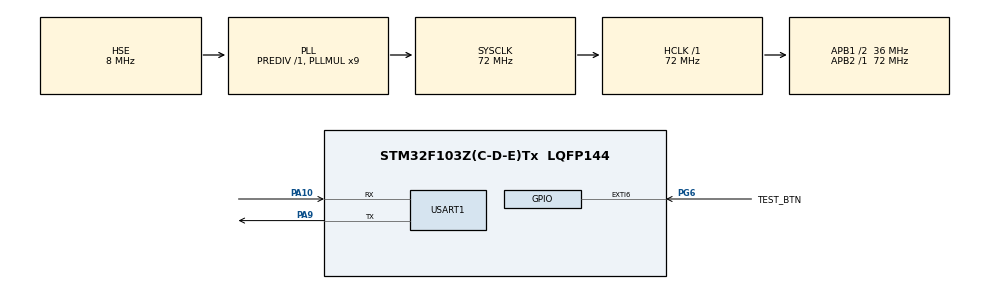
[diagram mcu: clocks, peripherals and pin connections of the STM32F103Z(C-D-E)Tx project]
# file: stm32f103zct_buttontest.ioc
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Mcu.Family=STM32F1
RCC.PLLSourceVirtual=RCC_PLLSOURCE_HSE
PC15-OSC32_OUT.Mode=LSE-External-Oscillator
PG6.Signal=GPXTI6
PA10.Mode=Asynchronous
PG6.GPIO_Label=TEST_BTN
RCC.APB1CLKDivider=RCC_HCLK_DIV2
PC14-OSC32_IN.Signal=RCC_OSC32_IN
RCC.SYSCLKSource=RCC_SYSCLKSOURCE_PLLCLK
ProjectManager.StackSize=0x400
PA13.Signal=SYS_JTMS-SWDIO
PA9.Mode=Asynchronous
ProjectManager.TargetToolchain=STM32CubeIDE
RCC.HCLKFreq_Value=72000000
RCC.APB2TimFreq_Value=72000000
PA9.Signal=USART1_TX
OSC_IN.Signal=RCC_OSC_IN
RCC.USBFreq_Value=72000000
OSC_OUT.Mode=HSE-External-Oscillator
PC15-OSC32_OUT.Signal=RCC_OSC32_OUT
OSC_OUT.Signal=RCC_OSC_OUT
RCC.AHBFreq_Value=72000000
board=custom
RCC.PLLMUL=RCC_PLL_MUL9
RCC.APB2Freq_Value=72000000
PG6.GPIO_PuPd=GPIO_PULLUP
PC14-OSC32_IN.Mode=LSE-External-Oscillator
PA14.Mode=Serial_Wire
PG6.GPIO_ModeDefaultEXTI=GPIO_MODE_IT_RISING_FALLING
PA13.Mode=Serial_Wire
Mcu.Name=STM32F103Z(C-D-E)Tx
RCC.SYSCLKFreq_VALUE=72000000
Mcu.Package=LQFP144
OSC_IN.Mode=HSE-External-Oscillator
USART1.VirtualMode=VM_ASYNC
NVIC.EXTI9_5_IRQn=true\:0\:0\:false\:false\:true\:true\:true
PA10.Signal=USART1_RX
PA14.Signal=SYS_JTCK-SWCLK
ProjectManager.HeapSize=0x200
NVIC.PriorityGroup=NVIC_PRIORITYGROUP_4
RCC.APB1TimFreq_Value=72000000
RCC.APB1Freq_Value=36000000

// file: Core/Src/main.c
/* USER CODE BEGIN Header */
/**
  ******************************************************************************
  * @file           : main.c
  * @brief          : Main program body
  ******************************************************************************
  * @attention
  *
  * <h2><center>&copy; Copyright (c) 2021 STMicroelectronics.
  * All rights reserved.</center></h2>
  *
  * This software component is licensed by ST under BSD 3-Clause license,
  * the "License"; You may not use this file except in compliance with the
  * License. You may obtain a copy of the License at:
  *                        opensource.org/licenses/BSD-3-Clause
  *
  ******************************************************************************
  */
/* USER CODE END Header */
#include "main.h"

/* USER CODE BEGIN Includes */
#include "Application.h"
/* USER CODE END Includes */

UART_HandleTypeDef huart1;

void SystemClock_Config(void);
static void MX_GPIO_Init(void);
static void MX_USART1_UART_Init(void);

int main(void)
{

    /* MCU Configuration--------------------------------------------------------*/

    /* Reset of all peripherals, Initializes the Flash interface and the Systick. */
    HAL_Init();

    /* Configure the system clock */
    SystemClock_Config();

    /* Initialize all configured peripherals */
    MX_GPIO_Init();
    MX_USART1_UART_Init();
    /* USER CODE BEGIN 2 */
    Application.init();
    /* USER CODE END 2 */

    /* Infinite loop */
    while (1) {
        Application.loop();
    }
}

void SystemClock_Config(void)
{
    RCC_OscInitTypeDef RCC_OscInitStruct = { 0 };
    RCC_ClkInitTypeDef RCC_ClkInitStruct = { 0 };

    /** Initializes the RCC Oscillators according to the specified parameters
  * in the RCC_OscInitTypeDef structure.
  */
    RCC_OscInitStruct.OscillatorType = RCC_OSCILLATORTYPE_HSE;
    RCC_OscInitStruct.HSEState = RCC_HSE_ON;
    RCC_OscInitStruct.HSEPredivValue = RCC_HSE_PREDIV_DIV1;
    RCC_OscInitStruct.HSIState = RCC_HSI_ON;
    RCC_OscInitStruct.PLL.PLLState = RCC_PLL_ON;
    RCC_OscInitStruct.PLL.PLLSource = RCC_PLLSOURCE_HSE;
    RCC_OscInitStruct.PLL.PLLMUL = RCC_PLL_MUL9;
    if (HAL_RCC_OscConfig(&RCC_OscInitStruct) != HAL_OK) {
        Error_Handler();
    }
    /** Initializes the CPU, AHB and APB buses clocks
  */
    RCC_ClkInitStruct.ClockType = RCC_CLOCKTYPE_HCLK | RCC_CLOCKTYPE_SYSCLK
        | RCC_CLOCKTYPE_PCLK1 | RCC_CLOCKTYPE_PCLK2;
    RCC_ClkInitStruct.SYSCLKSource = RCC_SYSCLKSOURCE_PLLCLK;
    RCC_ClkInitStruct.AHBCLKDivider = RCC_SYSCLK_DIV1;
    RCC_ClkInitStruct.APB1CLKDivider = RCC_HCLK_DIV2;
    RCC_ClkInitStruct.APB2CLKDivider = RCC_HCLK_DIV1;

    if (HAL_RCC_ClockConfig(&RCC_ClkInitStruct, FLASH_LATENCY_2) != HAL_OK) {
        Error_Handler();
    }
}

static void MX_USART1_UART_Init(void)
{

    huart1.Instance = USART1;
    huart1.Init.BaudRate = 115200;
    huart1.Init.WordLength = UART_WORDLENGTH_8B;
    huart1.Init.StopBits = UART_STOPBITS_1;
    huart1.Init.Parity = UART_PARITY_NONE;
    huart1.Init.Mode = UART_MODE_TX_RX;
    huart1.Init.HwFlowCtl = UART_HWCONTROL_NONE;
    huart1.Init.OverSampling = UART_OVERSAMPLING_16;
    if (HAL_UART_Init(&huart1) != HAL_OK) {
        Error_Handler();
    }
}

static void MX_GPIO_Init(void)
{
    GPIO_InitTypeDef GPIO_InitStruct = { 0 };

    /* GPIO Ports Clock Enable */
    __HAL_RCC_GPIOC_CLK_ENABLE();
    __HAL_RCC_GPIOG_CLK_ENABLE();
    __HAL_RCC_GPIOA_CLK_ENABLE();

    /*Configure GPIO pin : TEST_BTN_Pin */
    GPIO_InitStruct.Pin = TEST_BTN_Pin;
    GPIO_InitStruct.Mode = GPIO_MODE_IT_RISING_FALLING;
    GPIO_InitStruct.Pull = GPIO_PULLUP;
    HAL_GPIO_Init(TEST_BTN_GPIO_Port, &GPIO_InitStruct);

    /* EXTI interrupt init*/
    HAL_NVIC_SetPriority(EXTI9_5_IRQn, 0, 0);
    HAL_NVIC_EnableIRQ(EXTI9_5_IRQn);
}

void Error_Handler(void)
{
    __disable_irq();
    while (1) {
    }
}

/************************ (C) COPYRIGHT STMicroelectronics *****END OF FILE****/
